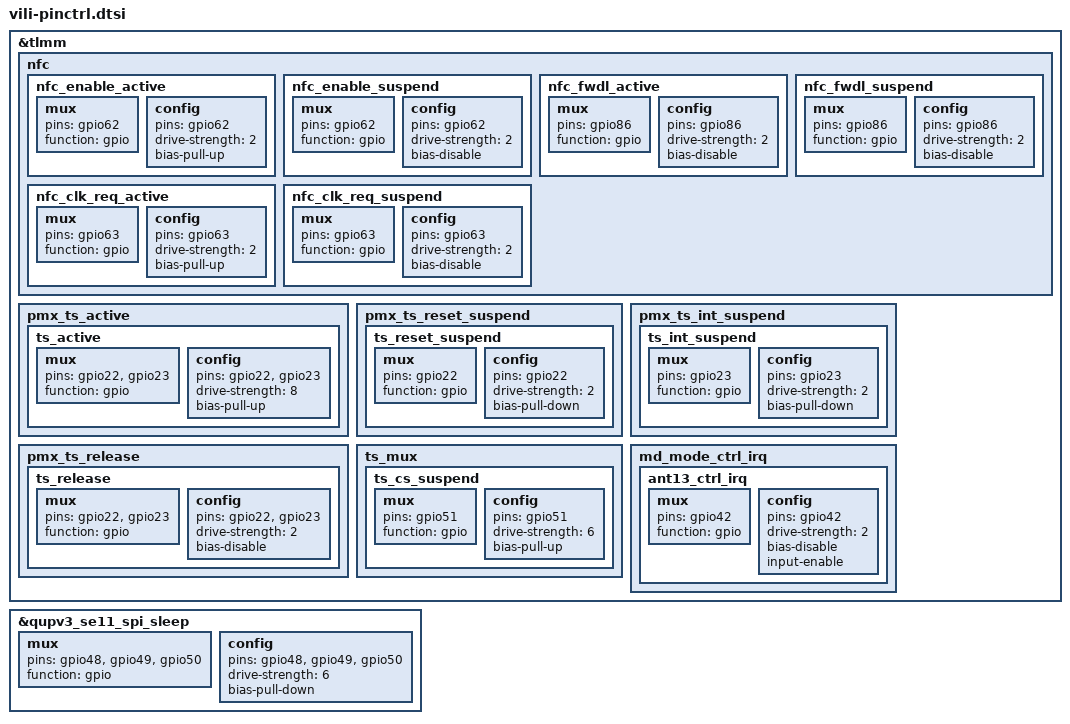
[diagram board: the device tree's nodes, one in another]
/*for vili pinctrl */
&tlmm {
	nfc {
			nfc_enable_active: nfc_enable_active {
				mux {
					pins = "gpio62";
					function = "gpio";
				};

				config {
					pins = "gpio62";
					drive-strength = <2>; /* 2 MA */
					bias-pull-up;
				};
			};

			nfc_enable_suspend: nfc_enable_suspend {
				mux {
					pins = "gpio62";
					function = "gpio";
				};

				config {
					pins = "gpio62";
					drive-strength = <2>; /* 2 MA */
					bias-disable;
				};
			};

			nfc_fwdl_active: nfc_fwdl_active {
				mux {
					/* 86: Firmware */
					pins = "gpio86";
					function = "gpio";
				};

				config {
					pins = "gpio86";
					drive-strength = <2>; /* 2 MA */
					bias-disable;
				};
			};

			nfc_fwdl_suspend: nfc_fwdl_suspend {
				mux {
					/*86: Firmware */
					pins = "gpio86";
					function = "gpio";
				};

				config {
					pins = "gpio86";
					drive-strength = <2>; /* 2 MA */
					bias-disable;
				};
			};

			nfc_clk_req_active: nfc_clk_req_active {
				/* active state */
				mux {
					/* GPIO 63: NFC CLOCK REQUEST */
					pins = "gpio63";
					function = "gpio";
				};

				config {
					pins = "gpio63";
					drive-strength = <2>; /* 2 MA */
					bias-pull-up;
				};
			};

			nfc_clk_req_suspend: nfc_clk_req_suspend {
				/* sleep state */
				mux {
					/* GPIO 63: NFC CLOCK REQUEST */
					pins = "gpio63";
					function = "gpio";
				};

				config {
					pins = "gpio63";
					drive-strength = <2>; /* 2 MA */
					bias-disable;
				};
			};
	};

	/* touchscreen 0 pins */
	pmx_ts_active {
		ts_active: ts_active {
			mux {
				pins = "gpio22", "gpio23";
				function = "gpio";
			};

			config {
				pins = "gpio22", "gpio23";
				drive-strength = <8>;
				bias-pull-up;
			};
		};
	};

	pmx_ts_reset_suspend {
		ts_reset_suspend: ts_reset_suspend {
			mux {
				pins = "gpio22";
				function = "gpio";
			};

			config {
				pins = "gpio22";
				drive-strength = <2>;
				bias-pull-down;
			};
		};
	};

	pmx_ts_int_suspend {
		ts_int_suspend: ts_int_suspend {
			mux {
				pins = "gpio23";
				function = "gpio";
			};

			config {
				pins = "gpio23";
				drive-strength = <2>;
				bias-pull-down;
			};
		};
	};

	pmx_ts_release {
		ts_release: ts_release {
			mux {
				pins = "gpio22", "gpio23";
				function = "gpio";
			};

			config {
				pins = "gpio22", "gpio23";
				drive-strength = <2>;
				bias-disable;
			};
		};
	};

	ts_mux {
		ts_cs_suspend: ts_cs_suspend {
			mux {
				pins = "gpio51";
				function = "gpio";
			};

			config {
				pins = "gpio51";
				drive-strength = <6>;
				bias-pull-up;
			};
		};
	};

        md_mode_ctrl_irq {
		ant13_ctrl_irq: ant13_ctrl_irq {
			mux {
				pins = "gpio42";
				function = "gpio";
			};
			config {
				pins = "gpio42";
				drive-strength = <2>;
				bias-disable;
				input-enable;
			};
		};
	};
};

&qupv3_se11_spi_sleep {
	mux {
		pins = "gpio48", "gpio49", "gpio50";
		function = "gpio";
	};

	config {
		pins = "gpio48", "gpio49", "gpio50";
		drive-strength = <6>;
		bias-pull-down;
	};
};
